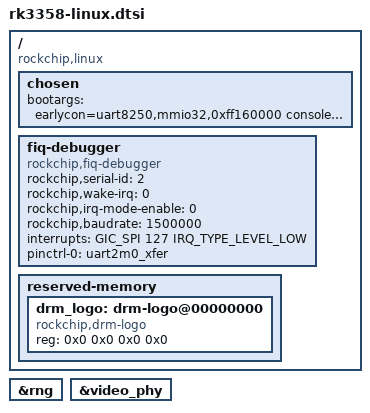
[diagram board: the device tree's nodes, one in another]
// SPDX-License-Identifier: (GPL-2.0+ OR MIT)
/*
 * Copyright (c) 2021 Rockchip Electronics Co., Ltd.
 *
 */

/ {
	compatible = "rockchip,linux", "rockchip,rk3358", "rockchip,px30";

	chosen {
		bootargs = "earlycon=uart8250,mmio32,0xff160000 console=ttyFIQ0 rw root=PARTUUID=614e0000-0000 rootwait";
	};

	fiq-debugger {
		compatible = "rockchip,fiq-debugger";
		rockchip,serial-id = <2>;
		rockchip,wake-irq = <0>;
		/* If enable uart uses irq instead of fiq */
		rockchip,irq-mode-enable = <0>;
		rockchip,baudrate = <1500000>;  /* Only 115200 and 1500000 */
		interrupts = <GIC_SPI 127 IRQ_TYPE_LEVEL_LOW>;
		pinctrl-names = "default";
		pinctrl-0 = <&uart2m0_xfer>;
		status = "okay";
	};

	reserved-memory {
		#address-cells = <2>;
		#size-cells = <2>;
		ranges;

		drm_logo: drm-logo@00000000 {
			compatible = "rockchip,drm-logo";
			reg = <0x0 0x0 0x0 0x0>;
		};
	};
};

&rng {
	status = "okay";
};

&video_phy {
	status = "okay";
};
